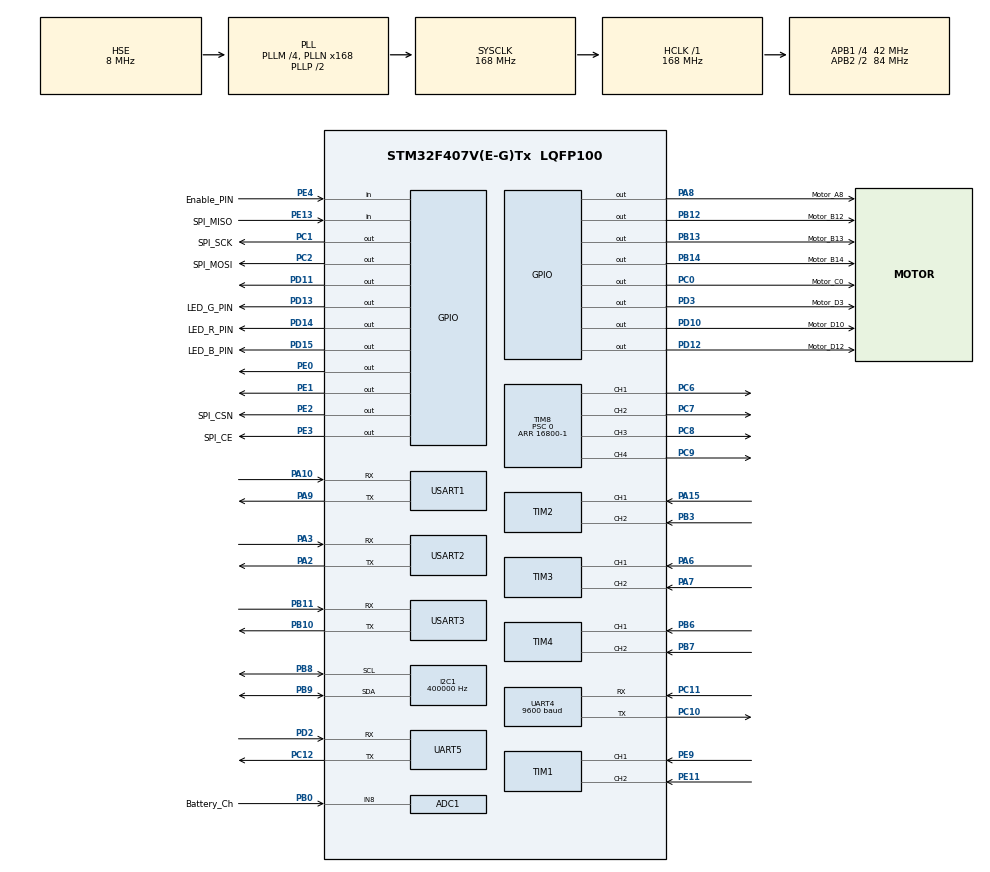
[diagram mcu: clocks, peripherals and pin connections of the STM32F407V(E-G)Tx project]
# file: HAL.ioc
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ADC1.Channel-0\#ChannelRegularConversion=ADC_CHANNEL_8
ADC1.InjNumberOfConversion=0
ADC1.NbrOfConversion=1
ADC1.NbrOfConversionFlag=1
ADC1.Rank-0\#ChannelRegularConversion=1
ADC1.SamplingTime-0\#ChannelRegularConversion=ADC_SAMPLETIME_84CYCLES
ADC1.master=1
Dma.Request0=USART1_RX
Dma.Request1=USART1_TX
Dma.Request2=UART4_RX
Dma.Request3=UART4_TX
Dma.Request4=USART2_RX
Dma.Request5=USART3_RX
Dma.Request6=UART5_RX
Dma.Request7=UART5_TX
Dma.UART4_RX.2.Direction=DMA_PERIPH_TO_MEMORY
Dma.UART4_RX.2.FIFOMode=DMA_FIFOMODE_DISABLE
Dma.UART4_RX.2.Instance=DMA1_Stream2
Dma.UART4_RX.2.MemDataAlignment=DMA_MDATAALIGN_BYTE
Dma.UART4_RX.2.MemInc=DMA_MINC_ENABLE
Dma.UART4_RX.2.Mode=DMA_NORMAL
Dma.UART4_RX.2.PeriphDataAlignment=DMA_PDATAALIGN_BYTE
Dma.UART4_RX.2.PeriphInc=DMA_PINC_DISABLE
Dma.UART4_RX.2.Priority=DMA_PRIORITY_LOW
Dma.UART4_TX.3.Direction=DMA_MEMORY_TO_PERIPH
Dma.UART4_TX.3.FIFOMode=DMA_FIFOMODE_DISABLE
Dma.UART4_TX.3.Instance=DMA1_Stream4
Dma.UART4_TX.3.MemDataAlignment=DMA_MDATAALIGN_BYTE
Dma.UART4_TX.3.MemInc=DMA_MINC_ENABLE
Dma.UART4_TX.3.Mode=DMA_NORMAL
Dma.UART4_TX.3.PeriphDataAlignment=DMA_PDATAALIGN_BYTE
Dma.UART4_TX.3.PeriphInc=DMA_PINC_DISABLE
Dma.UART4_TX.3.Priority=DMA_PRIORITY_LOW
Dma.UART5_RX.6.Direction=DMA_PERIPH_TO_MEMORY
Dma.UART5_RX.6.FIFOMode=DMA_FIFOMODE_DISABLE
Dma.UART5_RX.6.Instance=DMA1_Stream0
Dma.UART5_RX.6.MemDataAlignment=DMA_MDATAALIGN_BYTE
Dma.UART5_RX.6.MemInc=DMA_MINC_ENABLE
Dma.UART5_RX.6.Mode=DMA_NORMAL
Dma.UART5_RX.6.PeriphDataAlignment=DMA_PDATAALIGN_BYTE
Dma.UART5_RX.6.PeriphInc=DMA_PINC_DISABLE
Dma.UART5_RX.6.Priority=DMA_PRIORITY_LOW
Dma.UART5_TX.7.Direction=DMA_MEMORY_TO_PERIPH
Dma.UART5_TX.7.FIFOMode=DMA_FIFOMODE_DISABLE
Dma.UART5_TX.7.Instance=DMA1_Stream7
Dma.UART5_TX.7.MemDataAlignment=DMA_MDATAALIGN_BYTE
Dma.UART5_TX.7.MemInc=DMA_MINC_ENABLE
Dma.UART5_TX.7.Mode=DMA_NORMAL
Dma.UART5_TX.7.PeriphDataAlignment=DMA_PDATAALIGN_BYTE
Dma.UART5_TX.7.PeriphInc=DMA_PINC_DISABLE
Dma.UART5_TX.7.Priority=DMA_PRIORITY_LOW
Dma.USART1_RX.0.Direction=DMA_PERIPH_TO_MEMORY
Dma.USART1_RX.0.FIFOMode=DMA_FIFOMODE_DISABLE
Dma.USART1_RX.0.Instance=DMA2_Stream2
Dma.USART1_RX.0.MemDataAlignment=DMA_MDATAALIGN_BYTE
Dma.USART1_RX.0.MemInc=DMA_MINC_ENABLE
Dma.USART1_RX.0.Mode=DMA_NORMAL
Dma.USART1_RX.0.PeriphDataAlignment=DMA_PDATAALIGN_BYTE
Dma.USART1_RX.0.PeriphInc=DMA_PINC_DISABLE
Dma.USART1_RX.0.Priority=DMA_PRIORITY_LOW
Dma.USART1_TX.1.Direction=DMA_MEMORY_TO_PERIPH
Dma.USART1_TX.1.FIFOMode=DMA_FIFOMODE_DISABLE
Dma.USART1_TX.1.Instance=DMA2_Stream7
Dma.USART1_TX.1.MemDataAlignment=DMA_MDATAALIGN_BYTE
Dma.USART1_TX.1.MemInc=DMA_MINC_ENABLE
Dma.USART1_TX.1.Mode=DMA_NORMAL
Dma.USART1_TX.1.PeriphDataAlignment=DMA_PDATAALIGN_BYTE
Dma.USART1_TX.1.PeriphInc=DMA_PINC_DISABLE
Dma.USART1_TX.1.Priority=DMA_PRIORITY_LOW
Dma.USART2_RX.4.Direction=DMA_PERIPH_TO_MEMORY
Dma.USART2_RX.4.FIFOMode=DMA_FIFOMODE_DISABLE
Dma.USART2_RX.4.Instance=DMA1_Stream5
Dma.USART2_RX.4.MemDataAlignment=DMA_MDATAALIGN_BYTE
Dma.USART2_RX.4.MemInc=DMA_MINC_ENABLE
Dma.USART2_RX.4.Mode=DMA_NORMAL
Dma.USART2_RX.4.PeriphDataAlignment=DMA_PDATAALIGN_BYTE
Dma.USART2_RX.4.PeriphInc=DMA_PINC_DISABLE
Dma.USART2_RX.4.Priority=DMA_PRIORITY_LOW
Dma.USART3_RX.5.Direction=DMA_PERIPH_TO_MEMORY
Dma.USART3_RX.5.FIFOMode=DMA_FIFOMODE_DISABLE
Dma.USART3_RX.5.Instance=DMA1_Stream1
Dma.USART3_RX.5.MemDataAlignment=DMA_MDATAALIGN_BYTE
Dma.USART3_RX.5.MemInc=DMA_MINC_ENABLE
Dma.USART3_RX.5.Mode=DMA_NORMAL
Dma.USART3_RX.5.PeriphDataAlignment=DMA_PDATAALIGN_BYTE
Dma.USART3_RX.5.PeriphInc=DMA_PINC_DISABLE
Dma.USART3_RX.5.Priority=DMA_PRIORITY_HIGH
FREERTOS.Tasks01=BalanceTask,15,1024,StartBalanceTask,Default,NULL,Dynamic,NULL,NULL;UsartTask,15,1024,StartUsartTask,Default,NULL,Dynamic,NULL,NULL;IMUTask,16,512,StartIMUTask,Default,NULL,Dynamic,NULL,NULL;LedTask,8,512,StartLedTask,Default,NULL,Dynamic,NULL,NULL
I2C1.ClockSpeed=400000
I2C1.DutyCycle=I2C_DUTYCYCLE_16_9
I2C1.I2C_Mode=I2C_Fast
Mcu.Family=STM32F4
Mcu.Name=STM32F407V(E-G)Tx
Mcu.Package=LQFP100
NVIC.DMA1_Stream0_IRQn=true\:5\:0\:false\:false\:true\:true\:false\:true\:true
NVIC.DMA1_Stream1_IRQn=true\:5\:0\:false\:false\:true\:true\:false\:true\:true
NVIC.DMA1_Stream2_IRQn=true\:5\:0\:false\:false\:true\:true\:false\:true\:true
NVIC.DMA1_Stream4_IRQn=true\:5\:0\:false\:false\:true\:true\:false\:true\:true
NVIC.DMA1_Stream5_IRQn=true\:5\:0\:false\:false\:true\:true\:false\:true\:true
NVIC.DMA1_Stream7_IRQn=true\:5\:0\:false\:false\:true\:true\:false\:true\:true
NVIC.DMA2_Stream2_IRQn=true\:5\:0\:false\:false\:true\:true\:false\:true\:true
NVIC.DMA2_Stream7_IRQn=true\:5\:0\:false\:false\:true\:true\:false\:true\:true
NVIC.I2C1_ER_IRQn=true\:5\:0\:true\:false\:true\:true\:true\:true\:true
NVIC.I2C1_EV_IRQn=true\:5\:0\:true\:false\:true\:true\:true\:true\:true
NVIC.PriorityGroup=NVIC_PRIORITYGROUP_4
NVIC.TIM1_BRK_TIM9_IRQn=true\:15\:0\:false\:false\:true\:false\:false\:true\:true
NVIC.TIM6_DAC_IRQn=true\:5\:0\:true\:false\:true\:true\:true\:true\:true
NVIC.TIM7_IRQn=true\:5\:0\:true\:false\:true\:true\:true\:true\:true
NVIC.TimeBase=TIM1_BRK_TIM9_IRQn
NVIC.TimeBaseIP=TIM9
NVIC.UART4_IRQn=true\:5\:0\:true\:false\:true\:true\:true\:true\:true
NVIC.UART5_IRQn=true\:5\:0\:false\:false\:true\:true\:true\:true\:true
NVIC.USART1_IRQn=true\:5\:0\:true\:false\:true\:true\:true\:true\:true
NVIC.USART2_IRQn=true\:5\:0\:false\:false\:true\:true\:true\:true\:true
NVIC.USART3_IRQn=true\:5\:0\:false\:false\:true\:true\:true\:true\:true
PA0-WKUP.Mode=SYS_WakeUp0
PA0-WKUP.Signal=SYS_WKUP
PA10.GPIO_PuPd=GPIO_PULLUP
PA10.Mode=Asynchronous
PA10.Signal=USART1_RX
PA13.Mode=Serial_Wire
PA13.Signal=SYS_JTMS-SWDIO
PA14.Mode=Serial_Wire
PA14.Signal=SYS_JTCK-SWCLK
PA15.GPIO_PuPd=GPIO_PULLUP
PA15.Signal=S_TIM2_CH1_ETR
PA2.GPIO_PuPd=GPIO_PULLUP
PA2.Mode=Asynchronous
PA2.Signal=USART2_TX
PA3.GPIO_PuPd=GPIO_PULLUP
PA3.Mode=Asynchronous
PA3.Signal=USART2_RX
PA6.GPIO_PuPd=GPIO_PULLUP
PA6.Signal=S_TIM3_CH1
PA7.GPIO_PuPd=GPIO_PULLUP
PA7.Signal=S_TIM3_CH2
PA8.GPIO_Label=Motor_A8
PA8.GPIO_PuPd=GPIO_PULLUP
PA8.Signal=GPIO_Output
PA9.GPIO_PuPd=GPIO_PULLUP
PA9.Mode=Asynchronous
PA9.Signal=USART1_TX
PB0.GPIO_Label=Battery_Ch
PB0.Signal=ADCx_IN8
PB10.GPIO_PuPd=GPIO_PULLUP
PB10.Mode=Asynchronous
PB10.Signal=USART3_TX
PB11.GPIO_PuPd=GPIO_PULLUP
PB11.Mode=Asynchronous
PB11.Signal=USART3_RX
PB12.GPIO_Label=Motor_B12
PB12.GPIO_PuPd=GPIO_PULLUP
PB12.Signal=GPIO_Output
PB13.GPIO_Label=Motor_B13
PB13.GPIO_PuPd=GPIO_PULLUP
PB13.Signal=GPIO_Output
PB14.GPIO_Label=Motor_B14
PB14.GPIO_PuPd=GPIO_PULLUP
PB14.Signal=GPIO_Output
PB3.GPIO_PuPd=GPIO_PULLUP
PB3.Signal=S_TIM2_CH2
PB6.GPIO_PuPd=GPIO_PULLUP
PB6.Signal=S_TIM4_CH1
PB7.GPIO_PuPd=GPIO_PULLUP
PB7.Signal=S_TIM4_CH2
PB8.GPIO_Pu=GPIO_PULLUP
PB8.Mode=I2C
PB8.Signal=I2C1_SCL
PB9.GPIO_Pu=GPIO_PULLUP
PB9.Mode=I2C
PB9.Signal=I2C1_SDA
PC0.GPIO_Label=Motor_C0
PC0.GPIO_PuPd=GPIO_PULLUP
PC0.Signal=GPIO_Output
PC1.GPIO_Label=SPI_SCK
PC1.Signal=GPIO_Output
PC10.GPIO_PuPd=GPIO_PULLUP
PC10.Mode=Asynchronous
PC10.Signal=UART4_TX
PC11.GPIO_PuPd=GPIO_PULLUP
PC11.Mode=Asynchronous
PC11.Signal=UART4_RX
PC12.GPIO_PuPd=GPIO_PULLUP
PC12.Mode=Asynchronous
PC12.Signal=UART5_TX
PC2.GPIO_Label=SPI_MOSI
PC2.Signal=GPIO_Output
PC6.GPIO_PuPd=GPIO_PULLUP
PC6.GPIO_Speed=GPIO_SPEED_FREQ_VERY_HIGH
PC6.Signal=S_TIM8_CH1
PC7.GPIO_PuPd=GPIO_PULLUP
PC7.GPIO_Speed=GPIO_SPEED_FREQ_VERY_HIGH
PC7.Signal=S_TIM8_CH2
PC8.GPIO_PuPd=GPIO_PULLUP
PC8.GPIO_Speed=GPIO_SPEED_FREQ_VERY_HIGH
PC8.Signal=S_TIM8_CH3
PC9.GPIO_PuPd=GPIO_PULLUP
PC9.GPIO_Speed=GPIO_SPEED_FREQ_VERY_HIGH
PC9.Signal=S_TIM8_CH4
PD10.GPIO_Label=Motor_D10
PD10.Signal=GPIO_Output
PD11.GPIO_Speed=GPIO_SPEED_FREQ_VERY_HIGH
PD11.Signal=GPIO_Output
PD12.GPIO_Label=Motor_D12
PD12.GPIO_PuPd=GPIO_PULLUP
PD12.Signal=GPIO_Output
PD13.GPIO_Label=LED_G_PIN
PD13.GPIO_PuPd=GPIO_PULLUP
PD13.PinState=GPIO_PIN_SET
PD13.Signal=GPIO_Output
PD14.GPIO_Label=LED_R_PIN
PD14.GPIO_PuPd=GPIO_PULLUP
PD14.PinState=GPIO_PIN_SET
PD14.Signal=GPIO_Output
PD15.GPIO_Label=LED_B_PIN
PD15.GPIO_PuPd=GPIO_PULLUP
PD15.PinState=GPIO_PIN_SET
PD15.Signal=GPIO_Output
PD2.GPIO_PuPd=GPIO_PULLUP
PD2.Mode=Asynchronous
PD2.Signal=UART5_RX
PD3.GPIO_Label=Motor_D3
PD3.GPIO_ModeDefaultOutputPP=GPIO_MODE_OUTPUT_PP
PD3.GPIO_PuPd=GPIO_PULLUP
PD3.Signal=GPIO_Output
PE0.GPIO_PuPd=GPIO_PULLUP
PE0.Signal=GPIO_Output
PE1.GPIO_PuPd=GPIO_PULLUP
PE1.Signal=GPIO_Output
PE11.GPIO_ModeDefaultPP=GPIO_MODE_AF_PP
PE11.GPIO_PuPd=GPIO_PULLUP
PE11.Signal=S_TIM1_CH2
PE13.GPIO_Label=SPI_MISO
PE13.GPIO_PuPd=GPIO_PULLUP
PE13.Signal=GPIO_Input
PE2.GPIO_Label=SPI_CSN
PE2.GPIO_ModeDefaultOutputPP=GPIO_MODE_OUTPUT_PP
PE2.GPIO_PuPd=GPIO_PULLUP
PE2.Signal=GPIO_Output
PE3.GPIO_Label=SPI_CE
PE3.Signal=GPIO_Output
PE4.GPIO_Label=Enable_PIN
PE4.GPIO_PuPd=GPIO_PULLUP
PE4.Signal=GPIO_Input
PE9.GPIO_ModeDefaultPP=GPIO_MODE_AF_PP
PE9.GPIO_PuPd=GPIO_PULLUP
PE9.Signal=S_TIM1_CH1
PH0-OSC_IN.Mode=HSE-External-Oscillator
PH0-OSC_IN.Signal=RCC_OSC_IN
PH1-OSC_OUT.Mode=HSE-External-Oscillator
PH1-OSC_OUT.Signal=RCC_OSC_OUT
ProjectManager.HeapSize=0x200
ProjectManager.StackSize=0x400
ProjectManager.TargetToolchain=MDK-ARM V5.27
RCC.48MHZClocksFreq_Value=84000000
RCC.AHBFreq_Value=168000000
RCC.APB1CLKDivider=RCC_HCLK_DIV4
RCC.APB1Freq_Value=42000000
RCC.APB1TimFreq_Value=84000000
RCC.APB2CLKDivider=RCC_HCLK_DIV2
RCC.APB2Freq_Value=84000000
RCC.APB2TimFreq_Value=168000000
RCC.CortexFreq_Value=168000000
RCC.HCLKFreq_Value=168000000
RCC.HSE_VALUE=8000000
RCC.HSI_VALUE=16000000
RCC.LSE_VALUE=32768
RCC.PLLM=4
RCC.PLLN=168
RCC.PLLSourceVirtual=RCC_PLLSOURCE_HSE
RCC.SYSCLKFreq_VALUE=168000000
RCC.SYSCLKSource=RCC_SYSCLKSOURCE_PLLCLK
RCC.VCOOutputFreq_Value=336000000
SH.ADCx_IN8.0=ADC1_IN8,IN8
SH.S_TIM1_CH1.0=TIM1_CH1,Encoder_Interface
SH.S_TIM1_CH2.0=TIM1_CH2,Encoder_Interface
SH.S_TIM2_CH1_ETR.0=TIM2_CH1,Encoder_Interface
SH.S_TIM2_CH2.0=TIM2_CH2,Encoder_Interface
SH.S_TIM3_CH1.0=TIM3_CH1,Encoder_Interface
SH.S_TIM3_CH2.0=TIM3_CH2,Encoder_Interface
SH.S_TIM4_CH1.0=TIM4_CH1,Encoder_Interface
SH.S_TIM4_CH2.0=TIM4_CH2,Encoder_Interface
SH.S_TIM8_CH1.0=TIM8_CH1,PWM Generation1 CH1
SH.S_TIM8_CH2.0=TIM8_CH2,PWM Generation2 CH2
SH.S_TIM8_CH3.0=TIM8_CH3,PWM Generation3 CH3
SH.S_TIM8_CH4.0=TIM8_CH4,PWM Generation4 CH4
TIM1.EncoderMode=TIM_ENCODERMODE_TI12
TIM3.EncoderMode=TIM_ENCODERMODE_TI12
TIM4.EncoderMode=TIM_ENCODERMODE_TI12
TIM4.IC2Polarity=TIM_ICPOLARITY_FALLING
TIM6.AutoReloadPreload=TIM_AUTORELOAD_PRELOAD_ENABLE
TIM6.Period=499
TIM6.Prescaler=83
TIM7.AutoReloadPreload=TIM_AUTORELOAD_PRELOAD_ENABLE
TIM7.Period=9999
TIM7.Prescaler=83
TIM8.AutoReloadPreload=TIM_AUTORELOAD_PRELOAD_ENABLE
TIM8.Channel-PWM\ Generation1\ CH1=TIM_CHANNEL_1
TIM8.Channel-PWM\ Generation2\ CH2=TIM_CHANNEL_2
TIM8.Channel-PWM\ Generation3\ CH3=TIM_CHANNEL_3
TIM8.Channel-PWM\ Generation4\ CH4=TIM_CHANNEL_4
TIM8.ClockDivision=TIM_CLOCKDIVISION_DIV1
TIM8.OCIdleState_1=TIM_OCIDLESTATE_RESET
TIM8.OCPolarity_1=TIM_OCPOLARITY_HIGH
TIM8.Period=16800-1
TIM8.Prescaler=0
UART4.BaudRate=9600
UART4.VirtualMode=Asynchronous
UART5.VirtualMode=Asynchronous
USART1.VirtualMode=VM_ASYNC
USART2.VirtualMode=VM_ASYNC
USART3.VirtualMode=VM_ASYNC
VP_FREERTOS_VS_CMSIS_V2.Mode=CMSIS_V2
VP_SYS_VS_tim9.Mode=TIM9
VP_TIM6_VS_ClockSourceINT.Mode=Enable_Timer
VP_TIM7_VS_ClockSourceINT.Mode=Enable_Timer
VP_TIM8_VS_ClockSourceINT.Mode=Internal
board=custom

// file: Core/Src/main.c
/* USER CODE BEGIN Header */
/**
 ******************************************************************************
 * @file           : main.c
 * @brief          : Main program body
 ******************************************************************************
 * @attention
 *
 * Copyright (c) 2024 STMicroelectronics.
 * All rights reserved.
 *
 * This software is licensed under terms that can be found in the LICENSE file
 * in the root directory of this software component.
 * If no LICENSE file comes with this software, it is provided AS-IS.
 *
 ******************************************************************************
 */
/* USER CODE END Header */
#include "main.h"
#include "cmsis_os.h"

ADC_HandleTypeDef hadc1;

I2C_HandleTypeDef hi2c1;

TIM_HandleTypeDef htim1;
TIM_HandleTypeDef htim2;
TIM_HandleTypeDef htim3;
TIM_HandleTypeDef htim4;
TIM_HandleTypeDef htim6;
TIM_HandleTypeDef htim7;
TIM_HandleTypeDef htim8;

UART_HandleTypeDef huart4;
UART_HandleTypeDef huart5;
UART_HandleTypeDef huart1;
UART_HandleTypeDef huart2;
UART_HandleTypeDef huart3;
DMA_HandleTypeDef hdma_uart4_rx;
DMA_HandleTypeDef hdma_uart4_tx;
DMA_HandleTypeDef hdma_uart5_rx;
DMA_HandleTypeDef hdma_uart5_tx;
DMA_HandleTypeDef hdma_usart1_rx;
DMA_HandleTypeDef hdma_usart1_tx;
DMA_HandleTypeDef hdma_usart2_rx;
DMA_HandleTypeDef hdma_usart3_rx;

/* Definitions for BalanceTask */
osThreadId_t BalanceTaskHandle;
const osThreadAttr_t BalanceTask_attributes = {
  .name = "BalanceTask",
  .stack_size = 1024 * 4,
  .priority = (osPriority_t) osPriorityLow7,
};
/* Definitions for UsartTask */
osThreadId_t UsartTaskHandle;
const osThreadAttr_t UsartTask_attributes = {
  .name = "UsartTask",
  .stack_size = 1024 * 4,
  .priority = (osPriority_t) osPriorityLow7,
};
/* Definitions for IMUTask */
osThreadId_t IMUTaskHandle;
const osThreadAttr_t IMUTask_attributes = {
  .name = "IMUTask",
  .stack_size = 512 * 4,
  .priority = (osPriority_t) osPriorityBelowNormal,
};
/* Definitions for LedTask */
osThreadId_t LedTaskHandle;
const osThreadAttr_t LedTask_attributes = {
  .name = "LedTask",
  .stack_size = 512 * 4,
  .priority = (osPriority_t) osPriorityLow,
};
/* USER CODE BEGIN PV */

Vofa_HandleTypedef vofa_inst_binding_uart3;

uint32_t tim7_10ms_cnt = 0u;   // �??1比较
uint32_t tim7_1000ms_cnt = 0u; // �??100比较
float Angle_init;
bool Start_init = false;
/* USER CODE END PV */

void SystemClock_Config(void);
static void MX_GPIO_Init(void);
static void MX_DMA_Init(void);
static void MX_USART1_UART_Init(void);
static void MX_I2C1_Init(void);
static void MX_UART4_Init(void);
static void MX_USART3_UART_Init(void);
static void MX_ADC1_Init(void);
static void MX_TIM8_Init(void);
static void MX_TIM7_Init(void);
static void MX_TIM6_Init(void);
static void MX_USART2_UART_Init(void);
static void MX_TIM2_Init(void);
static void MX_TIM3_Init(void);
static void MX_TIM4_Init(void);
static void MX_TIM1_Init(void);
static void MX_UART5_Init(void);
void StartBalanceTask(void *argument);
void StartUsartTask(void *argument);
void StartIMUTask(void *argument);
void StartLedTask(void *argument);

/* USER CODE BEGIN 0 */

// int32_t compare_dir = 0;
// int32_t command = 0;
// uint8_t dbg_datarev_buff[32] = {0};

/* USER CODE END 0 */

int main(void)
{

  /* MCU Configuration--------------------------------------------------------*/

  /* Reset of all peripherals, Initializes the Flash interface and the Systick. */
  HAL_Init();

  /* Configure the system clock */
  SystemClock_Config();

  /* Initialize all configured peripherals */
  MX_GPIO_Init();
  MX_DMA_Init();
  MX_USART1_UART_Init();
  MX_I2C1_Init();
  MX_UART4_Init();
  MX_USART3_UART_Init();
  MX_ADC1_Init();
  MX_TIM8_Init();
  MX_TIM7_Init();
  MX_TIM6_Init();
  MX_USART2_UART_Init();
  MX_TIM2_Init();
  MX_TIM3_Init();
  MX_TIM4_Init();
  MX_TIM1_Init();
  MX_UART5_Init();
  /* USER CODE BEGIN 2 */
  systemInit();
  /* USER CODE END 2 */

  /* Init scheduler */
  osKernelInitialize();

  /* Create the thread(s) */
  /* creation of BalanceTask */
  BalanceTaskHandle = osThreadNew(StartBalanceTask, NULL, &BalanceTask_attributes);

  /* creation of UsartTask */
  UsartTaskHandle = osThreadNew(StartUsartTask, NULL, &UsartTask_attributes);

  /* creation of IMUTask */
  IMUTaskHandle = osThreadNew(StartIMUTask, NULL, &IMUTask_attributes);

  /* creation of LedTask */
  LedTaskHandle = osThreadNew(StartLedTask, NULL, &LedTask_attributes);

  /* Start scheduler */
  osKernelStart();

  /* We should never get here as control is now taken by the scheduler */

  /* Infinite loop */
  while (1)
  {

  }
}

void SystemClock_Config(void)
{
  RCC_OscInitTypeDef RCC_OscInitStruct = {0};
  RCC_ClkInitTypeDef RCC_ClkInitStruct = {0};

  /** Configure the main internal regulator output voltage
  */
  __HAL_RCC_PWR_CLK_ENABLE();
  __HAL_PWR_VOLTAGESCALING_CONFIG(PWR_REGULATOR_VOLTAGE_SCALE1);

  /** Initializes the RCC Oscillators according to the specified parameters
  * in the RCC_OscInitTypeDef structure.
  */
  RCC_OscInitStruct.OscillatorType = RCC_OSCILLATORTYPE_HSE;
  RCC_OscInitStruct.HSEState = RCC_HSE_ON;
  RCC_OscInitStruct.PLL.PLLState = RCC_PLL_ON;
  RCC_OscInitStruct.PLL.PLLSource = RCC_PLLSOURCE_HSE;
  RCC_OscInitStruct.PLL.PLLM = 4;
  RCC_OscInitStruct.PLL.PLLN = 168;
  RCC_OscInitStruct.PLL.PLLP = RCC_PLLP_DIV2;
  RCC_OscInitStruct.PLL.PLLQ = 4;
  if (HAL_RCC_OscConfig(&RCC_OscInitStruct) != HAL_OK)
  {
    Error_Handler();
  }

  /** Initializes the CPU, AHB and APB buses clocks
  */
  RCC_ClkInitStruct.ClockType = RCC_CLOCKTYPE_HCLK|RCC_CLOCKTYPE_SYSCLK
                              |RCC_CLOCKTYPE_PCLK1|RCC_CLOCKTYPE_PCLK2;
  RCC_ClkInitStruct.SYSCLKSource = RCC_SYSCLKSOURCE_PLLCLK;
  RCC_ClkInitStruct.AHBCLKDivider = RCC_SYSCLK_DIV1;
  RCC_ClkInitStruct.APB1CLKDivider = RCC_HCLK_DIV4;
  RCC_ClkInitStruct.APB2CLKDivider = RCC_HCLK_DIV2;

  if (HAL_RCC_ClockConfig(&RCC_ClkInitStruct, FLASH_LATENCY_5) != HAL_OK)
  {
    Error_Handler();
  }
}

static void MX_ADC1_Init(void)
{

  ADC_ChannelConfTypeDef sConfig = {0};

  /** Configure the global features of the ADC (Clock, Resolution, Data Alignment and number of conversion)
  */
  hadc1.Instance = ADC1;
  hadc1.Init.ClockPrescaler = ADC_CLOCK_SYNC_PCLK_DIV4;
  hadc1.Init.Resolution = ADC_RESOLUTION_12B;
  hadc1.Init.ScanConvMode = DISABLE;
  hadc1.Init.ContinuousConvMode = DISABLE;
  hadc1.Init.DiscontinuousConvMode = DISABLE;
  hadc1.Init.ExternalTrigConvEdge = ADC_EXTERNALTRIGCONVEDGE_NONE;
  hadc1.Init.ExternalTrigConv = ADC_SOFTWARE_START;
  hadc1.Init.DataAlign = ADC_DATAALIGN_RIGHT;
  hadc1.Init.NbrOfConversion = 1;
  hadc1.Init.DMAContinuousRequests = DISABLE;
  hadc1.Init.EOCSelection = ADC_EOC_SINGLE_CONV;
  if (HAL_ADC_Init(&hadc1) != HAL_OK)
  {
    Error_Handler();
  }

  /** Configure for the selected ADC regular channel its corresponding rank in the sequencer and its sample time.
  */
  sConfig.Channel = ADC_CHANNEL_8;
  sConfig.Rank = 1;
  sConfig.SamplingTime = ADC_SAMPLETIME_84CYCLES;
  if (HAL_ADC_ConfigChannel(&hadc1, &sConfig) != HAL_OK)
  {
    Error_Handler();
  }

}

static void MX_I2C1_Init(void)
{

  hi2c1.Instance = I2C1;
  hi2c1.Init.ClockSpeed = 400000;
  hi2c1.Init.DutyCycle = I2C_DUTYCYCLE_16_9;
  hi2c1.Init.OwnAddress1 = 0;
  hi2c1.Init.AddressingMode = I2C_ADDRESSINGMODE_7BIT;
  hi2c1.Init.DualAddressMode = I2C_DUALADDRESS_DISABLE;
  hi2c1.Init.OwnAddress2 = 0;
  hi2c1.Init.GeneralCallMode = I2C_GENERALCALL_DISABLE;
  hi2c1.Init.NoStretchMode = I2C_NOSTRETCH_DISABLE;
  if (HAL_I2C_Init(&hi2c1) != HAL_OK)
  {
    Error_Handler();
  }

}

static void MX_TIM1_Init(void)
{

  TIM_Encoder_InitTypeDef sConfig = {0};
  TIM_MasterConfigTypeDef sMasterConfig = {0};

  htim1.Instance = TIM1;
  htim1.Init.Prescaler = 0;
  htim1.Init.CounterMode = TIM_COUNTERMODE_UP;
  htim1.Init.Period = 65535;
  htim1.Init.ClockDivision = TIM_CLOCKDIVISION_DIV1;
  htim1.Init.RepetitionCounter = 0;
  htim1.Init.AutoReloadPreload = TIM_AUTORELOAD_PRELOAD_DISABLE;
  sConfig.EncoderMode = TIM_ENCODERMODE_TI12;
  sConfig.IC1Polarity = TIM_ICPOLARITY_RISING;
  sConfig.IC1Selection = TIM_ICSELECTION_DIRECTTI;
  sConfig.IC1Prescaler = TIM_ICPSC_DIV1;
  sConfig.IC1Filter = 0;
  sConfig.IC2Polarity = TIM_ICPOLARITY_RISING;
  sConfig.IC2Selection = TIM_ICSELECTION_DIRECTTI;
  sConfig.IC2Prescaler = TIM_ICPSC_DIV1;
  sConfig.IC2Filter = 0;
  if (HAL_TIM_Encoder_Init(&htim1, &sConfig) != HAL_OK)
  {
    Error_Handler();
  }
  sMasterConfig.MasterOutputTrigger = TIM_TRGO_RESET;
  sMasterConfig.MasterSlaveMode = TIM_MASTERSLAVEMODE_DISABLE;
  if (HAL_TIMEx_MasterConfigSynchronization(&htim1, &sMasterConfig) != HAL_OK)
  {
    Error_Handler();
  }

}

static void MX_TIM2_Init(void)
{

  TIM_Encoder_InitTypeDef sConfig = {0};
  TIM_MasterConfigTypeDef sMasterConfig = {0};

  htim2.Instance = TIM2;
  htim2.Init.Prescaler = 0;
  htim2.Init.CounterMode = TIM_COUNTERMODE_UP;
  htim2.Init.Period = 4294967295;
  htim2.Init.ClockDivision = TIM_CLOCKDIVISION_DIV1;
  htim2.Init.AutoReloadPreload = TIM_AUTORELOAD_PRELOAD_DISABLE;
  sConfig.EncoderMode = TIM_ENCODERMODE_TI1;
  sConfig.IC1Polarity = TIM_ICPOLARITY_RISING;
  sConfig.IC1Selection = TIM_ICSELECTION_DIRECTTI;
  sConfig.IC1Prescaler = TIM_ICPSC_DIV1;
  sConfig.IC1Filter = 0;
  sConfig.IC2Polarity = TIM_ICPOLARITY_RISING;
  sConfig.IC2Selection = TIM_ICSELECTION_DIRECTTI;
  sConfig.IC2Prescaler = TIM_ICPSC_DIV1;
  sConfig.IC2Filter = 0;
  if (HAL_TIM_Encoder_Init(&htim2, &sConfig) != HAL_OK)
  {
    Error_Handler();
  }
  sMasterConfig.MasterOutputTrigger = TIM_TRGO_RESET;
  sMasterConfig.MasterSlaveMode = TIM_MASTERSLAVEMODE_DISABLE;
  if (HAL_TIMEx_MasterConfigSynchronization(&htim2, &sMasterConfig) != HAL_OK)
  {
    Error_Handler();
  }

}

static void MX_TIM3_Init(void)
{

  TIM_Encoder_InitTypeDef sConfig = {0};
  TIM_MasterConfigTypeDef sMasterConfig = {0};

  htim3.Instance = TIM3;
  htim3.Init.Prescaler = 0;
  htim3.Init.CounterMode = TIM_COUNTERMODE_UP;
  htim3.Init.Period = 65535;
  htim3.Init.ClockDivision = TIM_CLOCKDIVISION_DIV1;
  htim3.Init.AutoReloadPreload = TIM_AUTORELOAD_PRELOAD_DISABLE;
  sConfig.EncoderMode = TIM_ENCODERMODE_TI12;
  sConfig.IC1Polarity = TIM_ICPOLARITY_RISING;
  sConfig.IC1Selection = TIM_ICSELECTION_DIRECTTI;
  sConfig.IC1Prescaler = TIM_ICPSC_DIV1;
  sConfig.IC1Filter = 0;
  sConfig.IC2Polarity = TIM_ICPOLARITY_RISING;
  sConfig.IC2Selection = TIM_ICSELECTION_DIRECTTI;
  sConfig.IC2Prescaler = TIM_ICPSC_DIV1;
  sConfig.IC2Filter = 0;
  if (HAL_TIM_Encoder_Init(&htim3, &sConfig) != HAL_OK)
  {
    Error_Handler();
  }
  sMasterConfig.MasterOutputTrigger = TIM_TRGO_RESET;
  sMasterConfig.MasterSlaveMode = TIM_MASTERSLAVEMODE_DISABLE;
  if (HAL_TIMEx_MasterConfigSynchronization(&htim3, &sMasterConfig) != HAL_OK)
  {
    Error_Handler();
  }

}

static void MX_TIM4_Init(void)
{

  TIM_Encoder_InitTypeDef sConfig = {0};
  TIM_MasterConfigTypeDef sMasterConfig = {0};

  htim4.Instance = TIM4;
  htim4.Init.Prescaler = 0;
  htim4.Init.CounterMode = TIM_COUNTERMODE_UP;
  htim4.Init.Period = 65535;
  htim4.Init.ClockDivision = TIM_CLOCKDIVISION_DIV1;
  htim4.Init.AutoReloadPreload = TIM_AUTORELOAD_PRELOAD_DISABLE;
  sConfig.EncoderMode = TIM_ENCODERMODE_TI12;
  sConfig.IC1Polarity = TIM_ICPOLARITY_RISING;
  sConfig.IC1Selection = TIM_ICSELECTION_DIRECTTI;
  sConfig.IC1Prescaler = TIM_ICPSC_DIV1;
  sConfig.IC1Filter = 0;
  sConfig.IC2Polarity = TIM_ICPOLARITY_FALLING;
  sConfig.IC2Selection = TIM_ICSELECTION_DIRECTTI;
  sConfig.IC2Prescaler = TIM_ICPSC_DIV1;
  sConfig.IC2Filter = 0;
  if (HAL_TIM_Encoder_Init(&htim4, &sConfig) != HAL_OK)
  {
    Error_Handler();
  }
  sMasterConfig.MasterOutputTrigger = TIM_TRGO_RESET;
  sMasterConfig.MasterSlaveMode = TIM_MASTERSLAVEMODE_DISABLE;
  if (HAL_TIMEx_MasterConfigSynchronization(&htim4, &sMasterConfig) != HAL_OK)
  {
    Error_Handler();
  }

}

static void MX_TIM6_Init(void)
{

  TIM_MasterConfigTypeDef sMasterConfig = {0};

  htim6.Instance = TIM6;
  htim6.Init.Prescaler = 83;
  htim6.Init.CounterMode = TIM_COUNTERMODE_UP;
  htim6.Init.Period = 499;
  htim6.Init.AutoReloadPreload = TIM_AUTORELOAD_PRELOAD_ENABLE;
  if (HAL_TIM_Base_Init(&htim6) != HAL_OK)
  {
    Error_Handler();
  }
  sMasterConfig.MasterOutputTrigger = TIM_TRGO_RESET;
  sMasterConfig.MasterSlaveMode = TIM_MASTERSLAVEMODE_DISABLE;
  if (HAL_TIMEx_MasterConfigSynchronization(&htim6, &sMasterConfig) != HAL_OK)
  {
    Error_Handler();
  }

}

static void MX_TIM7_Init(void)
{

  TIM_MasterConfigTypeDef sMasterConfig = {0};

  htim7.Instance = TIM7;
  htim7.Init.Prescaler = 83;
  htim7.Init.CounterMode = TIM_COUNTERMODE_UP;
  htim7.Init.Period = 9999;
  htim7.Init.AutoReloadPreload = TIM_AUTORELOAD_PRELOAD_ENABLE;
  if (HAL_TIM_Base_Init(&htim7) != HAL_OK)
  {
    Error_Handler();
  }
  sMasterConfig.MasterOutputTrigger = TIM_TRGO_RESET;
  sMasterConfig.MasterSlaveMode = TIM_MASTERSLAVEMODE_DISABLE;
  if (HAL_TIMEx_MasterConfigSynchronization(&htim7, &sMasterConfig) != HAL_OK)
  {
    Error_Handler();
  }

}

static void MX_TIM8_Init(void)
{

  TIM_ClockConfigTypeDef sClockSourceConfig = {0};
  TIM_MasterConfigTypeDef sMasterConfig = {0};
  TIM_OC_InitTypeDef sConfigOC = {0};
  TIM_BreakDeadTimeConfigTypeDef sBreakDeadTimeConfig = {0};

  htim8.Instance = TIM8;
  htim8.Init.Prescaler = 0;
  htim8.Init.CounterMode = TIM_COUNTERMODE_UP;
  htim8.Init.Period = 16800-1;
  htim8.Init.ClockDivision = TIM_CLOCKDIVISION_DIV1;
  htim8.Init.RepetitionCounter = 0;
  htim8.Init.AutoReloadPreload = TIM_AUTORELOAD_PRELOAD_ENABLE;
  if (HAL_TIM_Base_Init(&htim8) != HAL_OK)
  {
    Error_Handler();
  }
  sClockSourceConfig.ClockSource = TIM_CLOCKSOURCE_INTERNAL;
  if (HAL_TIM_ConfigClockSource(&htim8, &sClockSourceConfig) != HAL_OK)
  {
    Error_Handler();
  }
  if (HAL_TIM_PWM_Init(&htim8) != HAL_OK)
  {
    Error_Handler();
  }
  sMasterConfig.MasterOutputTrigger = TIM_TRGO_RESET;
  sMasterConfig.MasterSlaveMode = TIM_MASTERSLAVEMODE_DISABLE;
  if (HAL_TIMEx_MasterConfigSynchronization(&htim8, &sMasterConfig) != HAL_OK)
  {
    Error_Handler();
  }
  sConfigOC.OCMode = TIM_OCMODE_PWM1;
  sConfigOC.Pulse = 0;
  sConfigOC.OCPolarity = TIM_OCPOLARITY_HIGH;
  sConfigOC.OCNPolarity = TIM_OCNPOLARITY_HIGH;
  sConfigOC.OCFastMode = TIM_OCFAST_DISABLE;
  sConfigOC.OCIdleState = TIM_OCIDLESTATE_RESET;
  sConfigOC.OCNIdleState = TIM_OCNIDLESTATE_RESET;
  if (HAL_TIM_PWM_ConfigChannel(&htim8, &sConfigOC, TIM_CHANNEL_1) != HAL_OK)
  {
    Error_Handler();
  }
  if (HAL_TIM_PWM_ConfigChannel(&htim8, &sConfigOC, TIM_CHANNEL_2) != HAL_OK)
  {
    Error_Handler();
  }
  if (HAL_TIM_PWM_ConfigChannel(&htim8, &sConfigOC, TIM_CHANNEL_3) != HAL_OK)
  {
    Error_Handler();
  }
  if (HAL_TIM_PWM_ConfigChannel(&htim8, &sConfigOC, TIM_CHANNEL_4) != HAL_OK)
  {
    Error_Handler();
  }
  sBreakDeadTimeConfig.OffStateRunMode = TIM_OSSR_DISABLE;
  sBreakDeadTimeConfig.OffStateIDLEMode = TIM_OSSI_DISABLE;
  sBreakDeadTimeConfig.LockLevel = TIM_LOCKLEVEL_OFF;
  sBreakDeadTimeConfig.DeadTime = 0;
  sBreakDeadTimeConfig.BreakState = TIM_BREAK_DISABLE;
  sBreakDeadTimeConfig.BreakPolarity = TIM_BREAKPOLARITY_HIGH;
  sBreakDeadTimeConfig.AutomaticOutput = TIM_AUTOMATICOUTPUT_DISABLE;
  if (HAL_TIMEx_ConfigBreakDeadTime(&htim8, &sBreakDeadTimeConfig) != HAL_OK)
  {
    Error_Handler();
  }
  HAL_TIM_MspPostInit(&htim8);

}

static void MX_UART4_Init(void)
{

  huart4.Instance = UART4;
  huart4.Init.BaudRate = 9600;
  huart4.Init.WordLength = UART_WORDLENGTH_8B;
  huart4.Init.StopBits = UART_STOPBITS_1;
  huart4.Init.Parity = UART_PARITY_NONE;
  huart4.Init.Mode = UART_MODE_TX_RX;
  huart4.Init.HwFlowCtl = UART_HWCONTROL_NONE;
  huart4.Init.OverSampling = UART_OVERSAMPLING_16;
  if (HAL_UART_Init(&huart4) != HAL_OK)
  {
    Error_Handler();
  }

}

static void MX_UART5_Init(void)
{

  huart5.Instance = UART5;
  huart5.Init.BaudRate = 115200;
  huart5.Init.WordLength = UART_WORDLENGTH_8B;
  huart5.Init.StopBits = UART_STOPBITS_1;
  huart5.Init.Parity = UART_PARITY_NONE;
  huart5.Init.Mode = UART_MODE_TX_RX;
  huart5.Init.HwFlowCtl = UART_HWCONTROL_NONE;
  huart5.Init.OverSampling = UART_OVERSAMPLING_16;
  if (HAL_UART_Init(&huart5) != HAL_OK)
  {
    Error_Handler();
  }

}

static void MX_USART1_UART_Init(void)
{

  huart1.Instance = USART1;
  huart1.Init.BaudRate = 115200;
  huart1.Init.WordLength = UART_WORDLENGTH_8B;
  huart1.Init.StopBits = UART_STOPBITS_1;
  huart1.Init.Parity = UART_PARITY_NONE;
  huart1.Init.Mode = UART_MODE_TX_RX;
  huart1.Init.HwFlowCtl = UART_HWCONTROL_NONE;
  huart1.Init.OverSampling = UART_OVERSAMPLING_16;
  if (HAL_UART_Init(&huart1) != HAL_OK)
  {
    Error_Handler();
  }

}

static void MX_USART2_UART_Init(void)
{

  huart2.Instance = USART2;
  huart2.Init.BaudRate = 115200;
  huart2.Init.WordLength = UART_WORDLENGTH_8B;
  huart2.Init.StopBits = UART_STOPBITS_1;
  huart2.Init.Parity = UART_PARITY_NONE;
  huart2.Init.Mode = UART_MODE_TX_RX;
  huart2.Init.HwFlowCtl = UART_HWCONTROL_NONE;
  huart2.Init.OverSampling = UART_OVERSAMPLING_16;
  if (HAL_UART_Init(&huart2) != HAL_OK)
  {
    Error_Handler();
  }

}

static void MX_USART3_UART_Init(void)
{

  huart3.Instance = USART3;
  huart3.Init.BaudRate = 115200;
  huart3.Init.WordLength = UART_WORDLENGTH_8B;
  huart3.Init.StopBits = UART_STOPBITS_1;
  huart3.Init.Parity = UART_PARITY_NONE;
  huart3.Init.Mode = UART_MODE_TX_RX;
  huart3.Init.HwFlowCtl = UART_HWCONTROL_NONE;
  huart3.Init.OverSampling = UART_OVERSAMPLING_16;
  if (HAL_UART_Init(&huart3) != HAL_OK)
  {
    Error_Handler();
  }

}

static void MX_DMA_Init(void)
{

  /* DMA controller clock enable */
  __HAL_RCC_DMA2_CLK_ENABLE();
  __HAL_RCC_DMA1_CLK_ENABLE();

  /* DMA interrupt init */
  /* DMA1_Stream0_IRQn interrupt configuration */
  HAL_NVIC_SetPriority(DMA1_Stream0_IRQn, 5, 0);
  HAL_NVIC_EnableIRQ(DMA1_Stream0_IRQn);
  /* DMA1_Stream1_IRQn interrupt configuration */
  HAL_NVIC_SetPriority(DMA1_Stream1_IRQn, 5, 0);
  HAL_NVIC_EnableIRQ(DMA1_Stream1_IRQn);
  /* DMA1_Stream2_IRQn interrupt configuration */
  HAL_NVIC_SetPriority(DMA1_Stream2_IRQn, 5, 0);
  HAL_NVIC_EnableIRQ(DMA1_Stream2_IRQn);
  /* DMA1_Stream4_IRQn interrupt configuration */
  HAL_NVIC_SetPriority(DMA1_Stream4_IRQn, 5, 0);
  HAL_NVIC_EnableIRQ(DMA1_Stream4_IRQn);
  /* DMA1_Stream5_IRQn interrupt configuration */
  HAL_NVIC_SetPriority(DMA1_Stream5_IRQn, 5, 0);
  HAL_NVIC_EnableIRQ(DMA1_Stream5_IRQn);
  /* DMA1_Stream7_IRQn interrupt configuration */
  HAL_NVIC_SetPriority(DMA1_Stream7_IRQn, 5, 0);
  HAL_NVIC_EnableIRQ(DMA1_Stream7_IRQn);
  /* DMA2_Stream2_IRQn interrupt configuration */
  HAL_NVIC_SetPriority(DMA2_Stream2_IRQn, 5, 0);
  HAL_NVIC_EnableIRQ(DMA2_Stream2_IRQn);
  /* DMA2_Stream7_IRQn interrupt configuration */
  HAL_NVIC_SetPriority(DMA2_Stream7_IRQn, 5, 0);
  HAL_NVIC_EnableIRQ(DMA2_Stream7_IRQn);

}

static void MX_GPIO_Init(void)
{
  GPIO_InitTypeDef GPIO_InitStruct = {0};

  /* GPIO Ports Clock Enable */
  __HAL_RCC_GPIOE_CLK_ENABLE();
  __HAL_RCC_GPIOH_CLK_ENABLE();
  __HAL_RCC_GPIOC_CLK_ENABLE();
  __HAL_RCC_GPIOA_CLK_ENABLE();
  __HAL_RCC_GPIOB_CLK_ENABLE();
  __HAL_RCC_GPIOD_CLK_ENABLE();

  /*Configure GPIO pin Output Level */
  HAL_GPIO_WritePin(GPIOE, SPI_CSN_Pin|SPI_CE_Pin|GPIO_PIN_0|GPIO_PIN_1, GPIO_PIN_RESET);

  /*Configure GPIO pin Output Level */
  HAL_GPIO_WritePin(GPIOC, Motor_C0_Pin|SPI_SCK_Pin|SPI_MOSI_Pin, GPIO_PIN_RESET);

  /*Configure GPIO pin Output Level */
  HAL_GPIO_WritePin(GPIOB, Motor_B12_Pin|Motor_B13_Pin|Motor_B14_Pin, GPIO_PIN_RESET);

  /*Configure GPIO pin Output Level */
  HAL_GPIO_WritePin(GPIOD, Motor_D10_Pin|GPIO_PIN_11|Motor_D12_Pin|Motor_D3_Pin, GPIO_PIN_RESET);

  /*Configure GPIO pin Output Level */
  HAL_GPIO_WritePin(GPIOD, LED_G_PIN_Pin|LED_R_PIN_Pin|LED_B_PIN_Pin, GPIO_PIN_SET);

  /*Configure GPIO pin Output Level */
  HAL_GPIO_WritePin(Motor_A8_GPIO_Port, Motor_A8_Pin, GPIO_PIN_RESET);

  /*Configure GPIO pins : SPI_CSN_Pin PE0 PE1 */
  GPIO_InitStruct.Pin = SPI_CSN_Pin|GPIO_PIN_0|GPIO_PIN_1;
  GPIO_InitStruct.Mode = GPIO_MODE_OUTPUT_PP;
  GPIO_InitStruct.Pull = GPIO_PULLUP;
  GPIO_InitStruct.Speed = GPIO_SPEED_FREQ_LOW;
  HAL_GPIO_Init(GPIOE, &GPIO_InitStruct);

  /*Configure GPIO pin : SPI_CE_Pin */
  GPIO_InitStruct.Pin = SPI_CE_Pin;
  GPIO_InitStruct.Mode = GPIO_MODE_OUTPUT_PP;
  GPIO_InitStruct.Pull = GPIO_NOPULL;
  GPIO_InitStruct.Speed = GPIO_SPEED_FREQ_LOW;
  HAL_GPIO_Init(SPI_CE_GPIO_Port, &GPIO_InitStruct);

  /*Configure GPIO pins : Enable_PIN_Pin SPI_MISO_Pin */
  GPIO_InitStruct.Pin = Enable_PIN_Pin|SPI_MISO_Pin;
  GPIO_InitStruct.Mode = GPIO_MODE_INPUT;
  GPIO_InitStruct.Pull = GPIO_PULLUP;
  HAL_GPIO_Init(GPIOE, &GPIO_InitStruct);

  /*Configure GPIO pin : Motor_C0_Pin */
  GPIO_InitStruct.Pin = Motor_C0_Pin;
  GPIO_InitStruct.Mode = GPIO_MODE_OUTPUT_PP;
  GPIO_InitStruct.Pull = GPIO_PULLUP;
  GPIO_InitStruct.Speed = GPIO_SPEED_FREQ_LOW;
  HAL_GPIO_Init(Motor_C0_GPIO_Port, &GPIO_InitStruct);

  /*Configure GPIO pins : SPI_SCK_Pin SPI_MOSI_Pin */
  GPIO_InitStruct.Pin = SPI_SCK_Pin|SPI_MOSI_Pin;
  GPIO_InitStruct.Mode = GPIO_MODE_OUTPUT_PP;
  GPIO_InitStruct.Pull = GPIO_NOPULL;
  GPIO_InitStruct.Speed = GPIO_SPEED_FREQ_LOW;
  HAL_GPIO_Init(GPIOC, &GPIO_InitStruct);

  /*Configure GPIO pins : Motor_B12_Pin Motor_B13_Pin Motor_B14_Pin */
  GPIO_InitStruct.Pin = Motor_B12_Pin|Motor_B13_Pin|Motor_B14_Pin;
  GPIO_InitStruct.Mode = GPIO_MODE_OUTPUT_PP;
  GPIO_InitStruct.Pull = GPIO_PULLUP;
  GPIO_InitStruct.Speed = GPIO_SPEED_FREQ_LOW;
  HAL_GPIO_Init(GPIOB, &GPIO_InitStruct);

  /*Configure GPIO pin : Motor_D10_Pin */
  GPIO_InitStruct.Pin = Motor_D10_Pin;
  GPIO_InitStruct.Mode = GPIO_MODE_OUTPUT_PP;
  GPIO_InitStruct.Pull = GPIO_NOPULL;
  GPIO_InitStruct.Speed = GPIO_SPEED_FREQ_LOW;
  HAL_GPIO_Init(Motor_D10_GPIO_Port, &GPIO_InitStruct);

  /*Configure GPIO pin : PD11 */
  GPIO_InitStruct.Pin = GPIO_PIN_11;
  GPIO_InitStruct.Mode = GPIO_MODE_OUTPUT_PP;
  GPIO_InitStruct.Pull = GPIO_NOPULL;
  GPIO_InitStruct.Speed = GPIO_SPEED_FREQ_VERY_HIGH;
  HAL_GPIO_Init(GPIOD, &GPIO_InitStruct);

  /*Configure GPIO pins : Motor_D12_Pin LED_G_PIN_Pin LED_R_PIN_Pin LED_B_PIN_Pin
                           Motor_D3_Pin */
  GPIO_InitStruct.Pin = Motor_D12_Pin|LED_G_PIN_Pin|LED_R_PIN_Pin|LED_B_PIN_Pin
                          |Motor_D3_Pin;
  GPIO_InitStruct.Mode = GPIO_MODE_OUTPUT_PP;
  GPIO_InitStruct.Pull = GPIO_PULLUP;
  GPIO_InitStruct.Speed = GPIO_SPEED_FREQ_LOW;
  HAL_GPIO_Init(GPIOD, &GPIO_InitStruct);

  /*Configure GPIO pin : Motor_A8_Pin */
  GPIO_InitStruct.Pin = Motor_A8_Pin;
  GPIO_InitStruct.Mode = GPIO_MODE_OUTPUT_PP;
  GPIO_InitStruct.Pull = GPIO_PULLUP;
  GPIO_InitStruct.Speed = GPIO_SPEED_FREQ_LOW;
  HAL_GPIO_Init(Motor_A8_GPIO_Port, &GPIO_InitStruct);

}

void HAL_TIM_PeriodElapsedCallback(TIM_HandleTypeDef *htim)
{
  if (htim->Instance == TIM9)
  {
    HAL_IncTick();
  }
  /* USER CODE BEGIN Callback 1 */
  if (htim->Instance == TIM6)
  {
    HAL_GPIO_TogglePin(Buzzer_GPIO_Port, Buzzer_Pin);
  }
  /* USER CODE END Callback 1 */
}

void Error_Handler(void)
{
  __disable_irq();
  while (1)
  {
  }
}
